AUTOSAR XML (schema 00048)
package /AUTOLIV/SoftwareComponents/RCM
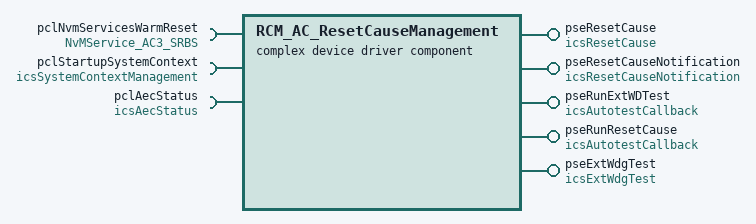
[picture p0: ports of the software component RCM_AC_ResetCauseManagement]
  complex device driver sw component type RCM_AC_ResetCauseManagement
    require port pclNvmServicesWarmReset: required-com-specs=[EraseBlock, InvalidateNvBlock, WriteBlock, ReadBlock, SetRamBlockStatus, GetErrorStatus], required-interface=NvMService_AC3_SRBS
    require port pclStartupSystemContext: required-interface=icsSystemContextManagement
      required-com-specs:
        GetBatteryHysteresisThrs
        GetLastTensionningState
        GetMonitoredCycle
        ManageSystemContextStorage
        RestoreSystemContext
        SuperviseKL30bg
    5 x provide port:
      pseResetCause: provided-interface=icsResetCause
        provided-com-specs:
          operation=ConfirmResetCause, queue-length=1
          operation=DetermineResetCause, queue-length=1
          operation=GetResetCause, queue-length=1
      pseResetCauseNotification: server-com-spec{operation=NotifyResetCause, queue-length=1}, provided-interface=icsResetCauseNotification  # RCM port for RCM to be notified by other SW modules of the cause which will lead to reset
      pseRunExtWDTest: server-com-spec{operation=AutotestCallback, queue-length=1}, provided-interface=icsAutotestCallback
      pseRunResetCause: server-com-spec{operation=AutotestCallback, queue-length=1}, provided-interface=icsAutotestCallback
      pseExtWdgTest: provided-com-specs=[{operation=LaunchWdgTest, queue-length=1}, {operation=GetWdgTestResult, queue-length=1}], provided-interface=icsExtWdgTest
    require port pclAecStatus: required-interface=icsAecStatus
      required-com-specs:
        SetAecEvent
        GetNumberOfImplementedAec
        GetAecStatus
        GetAecQualificationCount
        GetAecNvpBlockRecordingStatus
        GetAecGroupsStatus
        GetAecDeskillThrs
    behavior RCM_IB_ResetCauseManagement: data-type-mapping=DataTypeMappingSet_PP4G, port-api-option{enable-take-address=false, error-handling=NO-TRANSFORMER-ERROR-HANDLING, indirect-api=false, port=pseResetCause}
      6 x operation invoked event:
        oie_pseRunExtWDTest_AutotestCallback: start-on-event=RCM_Autotest_RunExtWDTest, operation=pseRunExtWDTest.AutotestCallback
        oie_pseRunresetCause_AutotestCallback: start-on-event=RCM_Autotest_RunResetCause, operation=pseRunResetCause.AutotestCallback
        RCM_evNotifyResetCause: start-on-event=RCM_runNotifyResetCause, operation=pseResetCauseNotification.NotifyResetCause
        OIT_RCM_runGetResetCause_pseResetCause_GetResetCause: start-on-event=RCM_runGetResetCause, operation=pseResetCause.GetResetCause
        OIT_RCM_runGetTestResult_pseExtWdgTest_GetWdgTestResult: start-on-event=RCM_runGetTestResult, operation=pseExtWdgTest.GetWdgTestResult
        OIT_RCM_runLaunchExtWdgTest_pseExtWdgTest_LaunchWdgTest: start-on-event=RCM_runLaunchExtWdgTest, operation=pseExtWdgTest.LaunchWdgTest
      init event RCM_runConfirmResetCause_InitEvent: start-on-event=RCM_runConfirmResetCause
      explicit-inter-runnable-variables:
        data u8ResetCause: sw-calibration-access=READ-ONLY, type=u32ResetCauseType_Appl, init-value=constant-reference=APPLINIT_KU32_RESET_CAUSE_UNKNOWN  # Reset cause computed by the RCM component
        data u8WdgTestResult: sw-calibration-access=READ-ONLY, type=u8WdgTestResultType_Appl, init-value=0
      8 x runnable:
        RCM_Autotest_RunExtWDTest: can-be-invoked-concurrently=true
          sync call SC_pclAecStatus_GetAecStatus: operation=pclAecStatus.GetAecStatus
        RCM_Autotest_RunResetCause: can-be-invoked-concurrently=true
        RCM_runConfirmResetCause: can-be-invoked-concurrently=true  # To confirm the computed reset cause based on some restored information
          read-local-variables:
            access Read_u8ResetCause: accessed-variable=u8ResetCause
          written-local-variables:
            access WRITE_u8ResetCause: accessed-variable=u8ResetCause
        RCM_runDetermineResetCause: can-be-invoked-concurrently=true  # To determine the reset cause
          sync call scp_ManageSystemContextStora: operation=pclStartupSystemContext.ManageSystemContextStorage
        RCM_runGetResetCause: can-be-invoked-concurrently=true
          read-local-variables:
            access Read_u8ResetCause: accessed-variable=u8ResetCause
          sync call SC_pclNvmServicesWarmReset_SetRamBlockStatus: operation=pclNvmServicesWarmReset.SetRamBlockStatus
        RCM_runNotifyResetCause: can-be-invoked-concurrently=true  # this function give sthe possibility to the rest of the SW application to store in protected memory section that a reset will be performed
        RCM_runGetTestResult: can-be-invoked-concurrently=true
        RCM_runLaunchExtWdgTest
  swc implementation RCM_impResetCauseManagement: behavior=RCM_IB_ResetCauseManagement
    code-descriptors:
      code RCM_Impl_Code: artifact-descriptors=autosar-engineering-object=category=SWSRC
